# RA4M1 register map
Vendor: Renesas Electronics Corporation; Series: RA4; File version: 1.2
CPU: CM4 r0p1, little endian, MPU, FPU, VTOR, 4 interrupt priority bits
Registers are 8-bit, read-write, reset 0x0 unless marked. A register's access mark holds for its fields unless they carry their own. Offsets are from the block's base; [hi:lo] are bit positions; {n}, {i} and the like mark numbered series; 'fields as' and 'values as' point back to an identical list.

## OPAMP — OperationalAmplifier
Base 0x40086000
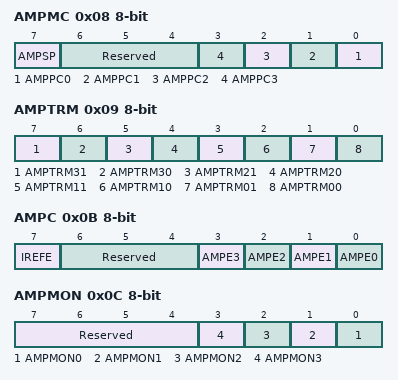
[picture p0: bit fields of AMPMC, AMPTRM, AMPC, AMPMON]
0x08 AMPMC — Operational amplifier mode control register
  [7] AMPSP — Operation mode selection
    0=Low-power mode (low-speed); 1=High-speed mode
  [6:4] Reserved — These bits are read as 000. The write value should be 000.
  [n] AMPPC{n} (n=0..3) — Operational amplifier precharge control status
    0=Precharging is stopped; 1=Precharging is enabled
0x09 AMPTRM — Operational amplifier trigger mode control register
  [7] AMPTRM31 — Operational amplifier function activation/stop trigger control
    0=Software trigger mode(AMPTRM30=0)/An activation trigger mode(AMPTRM30=1); 1=Setting prohibited(AMPTRM30=0)/An activation and A/D trigger mode(AMPTRM30=1)
  [6] AMPTRM30 — Operational amplifier function activation/stop trigger control
    0=Software trigger mode(AMPTRM31=0)/Setting prohibited(AMPTRM31=1); 1=An activation trigger mode(AMPTRM31=0)/An activation and A/D trigger mode(AMPTRM31=1)
  [5] AMPTRM21 — Operational amplifier function activation/stop trigger control
    0=Software trigger mode(AMPTRM20=0)/An activation trigger mode(AMPTRM20=1); 1=Setting prohibited(AMPTRM20=0)/An activation and A/D trigger mode(AMPTRM20=1)
  [4] AMPTRM20 — Operational amplifier function activation/stop trigger control
    0=Software trigger mode(AMPTRM21=0)/Setting prohibited(AMPTRM21=1); 1=An activation trigger mode(AMPTRM21=0)/An activation and A/D trigger mode(AMPTRM21=1)
  [3] AMPTRM11 — Operational amplifier function activation/stop trigger control
    0=Software trigger mode(AMPTRM10=0)/An activation trigger mode(AMPTRM10=1); 1=Setting prohibited(AMPTRM10=0)/An activation and A/D trigger mode(AMPTRM10=1)
  [2] AMPTRM10 — Operational amplifier function activation/stop trigger control
    0=Software trigger mode(AMPTRM11=0)/Setting prohibited(AMPTRM11=1); 1=An activation trigger mode(AMPTRM11=0)/An activation and A/D trigger mode(AMPTRM11=1)
  [1] AMPTRM01 — Operational amplifier function activation/stop trigger control
    0=Software trigger mode(AMPTRM00=0)/An activation trigger mode(AMPTRM00=1); 1=Setting prohibited(AMPTRM00=0)/An activation and A/D trigger mode(AMPTRM00=1)
  [0] AMPTRM00 — Operational amplifier function activation/stop trigger control
    0=Software trigger mode(AMPTRM01=0)/Setting prohibited(AMPTRM01=1); 1=An activation trigger mode(AMPTRM01=0)/An activation and A/D trigger mode(AMPTRM01=1)
0x0A AMPTRS — Operational Amplifier Activation Trigger Select Register
  [1:0] AMPTRS — ELC trigger selection Do not change the value of the AMPTRS register after setting the AMPTRM register.
    0=Operational amplifier 0: Operational amplifier An activation trigger 0.Operational amplifier 1: Operational amplifier An activation trigger 1.Operational amplifier 2: Operational amplifier An activation trigger 2.Operational amplifier 3: Operational amplifier An activation trigger 3; 1=Operational amplifier 0: Operational amplifier An activation trigger 0.Operational amplifier 1: Operational amplifier An activation trigger 0.Operational amplifier 2: Operational amplifier An activation trigger 1.Operational amplifier 3: Operational amplifier An activation trigger 1; 2=Setting prohibited; 3=Operational amplifier 0: Operational amplifier An activation trigger 0.Operational amplifier 1: Operational amplifier An activation trigger 0.Operational amplifier 2: Operational amplifier An activation trigger 0.Operational amplifier 3: Operational amplifier An activation trigger 0
0x0B AMPC — Operational amplifier control register
  [7] IREFE — Operation control of operational amplifier reference current circuit
    0=Operational amplifier reference current circuit is stopped; 1=Operation of operational amplifier reference current circuit is enabled
  [6:4] Reserved — These bits are read as 000. The write value should be 000.
  [3] AMPE3 — Operation control of operational amplifier(UNIT3)
    0=Operation amplifier is stopped; 1=Software trigger mode: Operation of operational amplifier is enabled Operation of the operational amplifier reference current circuit is also enabled regardless of the IREFE bit se An activation trigger mode or An activation and A/D trigger mode: Wait for An activation is enabled
  [2] AMPE2 — Operation control of operational amplifier(UNIT2)
    values as AMPE3
  [1] AMPE1 — Operation control of operational amplifier(UNIT1)
    values as AMPE3
  [0] AMPE0 — Operation control of operational amplifier(UNIT0)
    0=Operation amplifier is stopped; 1=Software trigger mode: Operation of operational amplifier is enabled Operation of the operational amplifier reference current circuit is also enabled regardless of the IREFE bit se An activation trigger mode or An activation and A/D trigger mode: Wait for AGT is enabled
0x0C AMPMON ro — Operational amplifier monitor register
  [7:4] Reserved — These bits are read as 0000.
  [n] AMPMON{n} (n=0..3) — Operational amplifier status(UNIT{n})
    0=Operational amplifier {n} is stopped; 1=Operational amplifier {n} is operating
